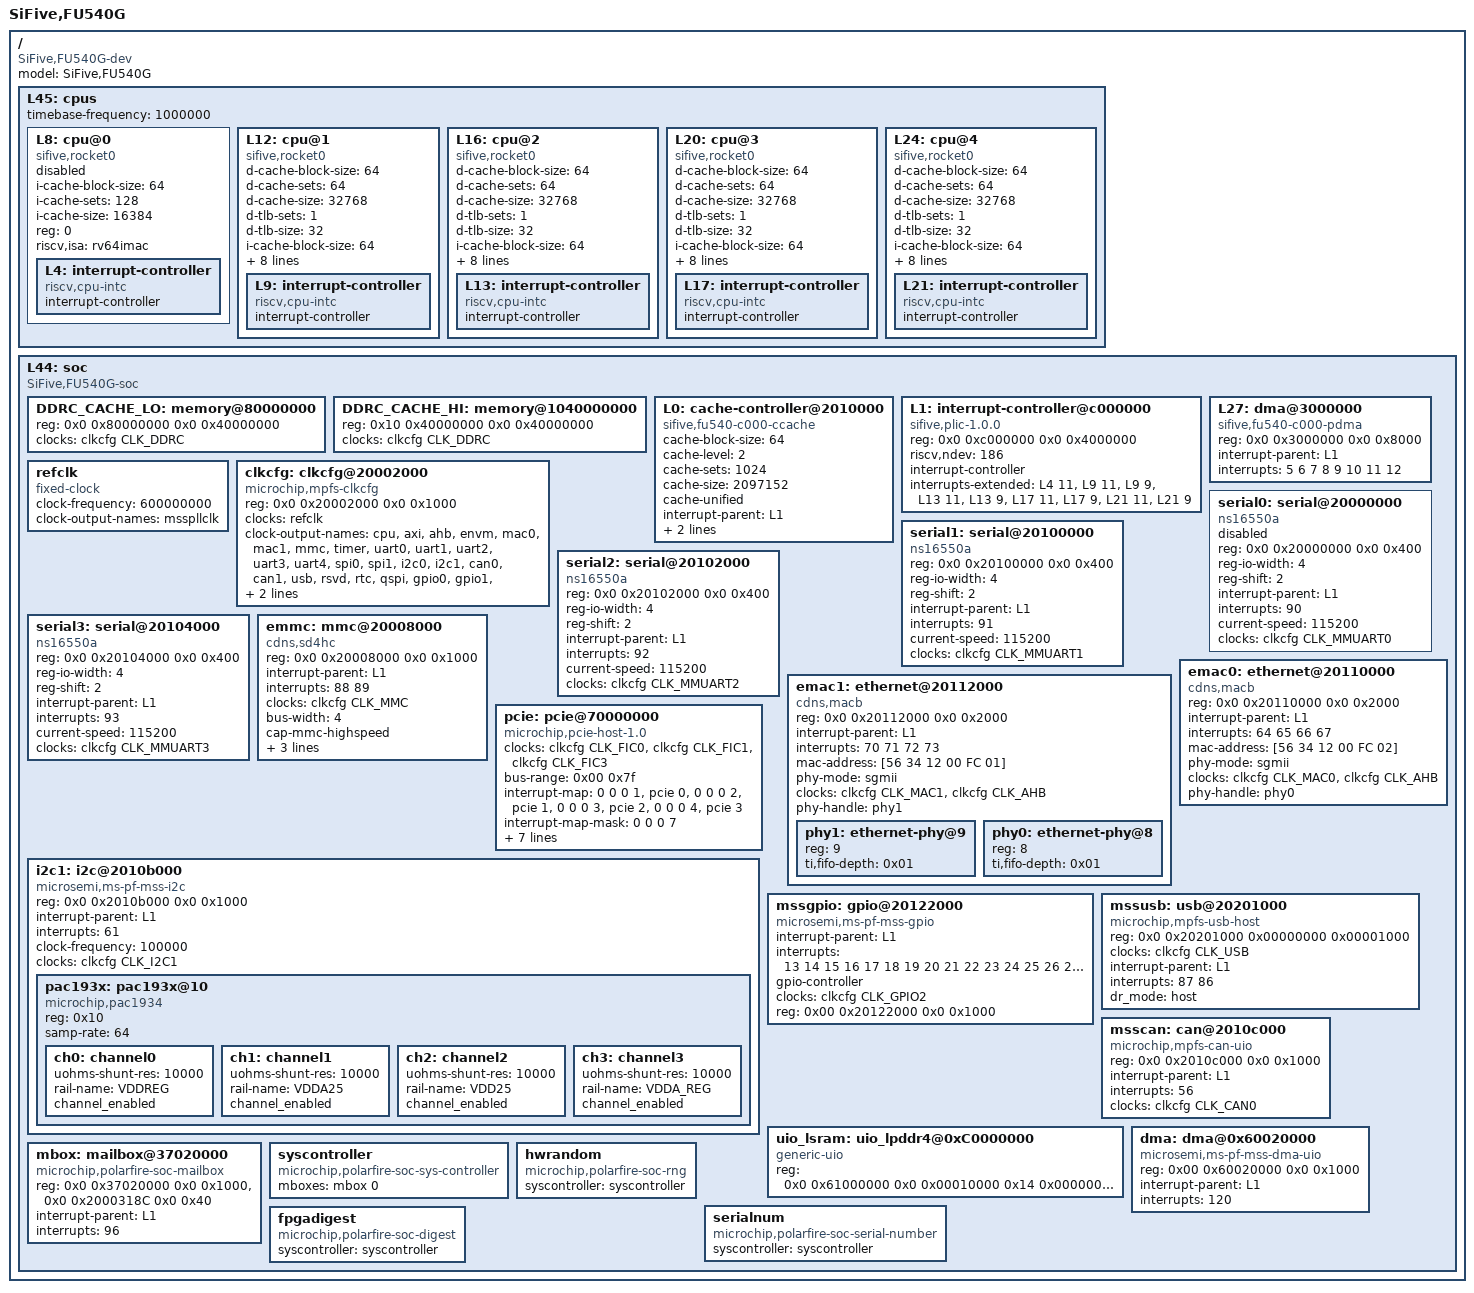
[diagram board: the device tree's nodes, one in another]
// SPDX-License-Identifier: (GPL-2.0 OR MIT)
/* Copyright (c) 2019-2020 Microchip Technology Inc */
/dts-v1/;
#include "dt-bindings/clock/microchip,mpfs-clock.h"
/ {
	#address-cells = <2>;
	#size-cells = <2>;
	compatible = "SiFive,FU540G-dev", "fu540-dev", "sifive-dev";
	model = "SiFive,FU540G";
	L45: cpus {
		#address-cells = <1>;
		#size-cells = <0>;
		timebase-frequency = <1000000>;
		L8: cpu@0 {
			compatible = "sifive,rocket0", "riscv";
			device_type = "cpu";
			i-cache-block-size = <64>;
			i-cache-sets = <128>;
			i-cache-size = <16384>;
			reg = <0>;
			riscv,isa = "rv64imac";
			status = "disabled";
			L4: interrupt-controller {
				#interrupt-cells = <1>;
				compatible = "riscv,cpu-intc";
				interrupt-controller;
			};
		};
		L12: cpu@1 {
			compatible = "sifive,rocket0", "riscv";
			d-cache-block-size = <64>;
			d-cache-sets = <64>;
			d-cache-size = <32768>;
			d-tlb-sets = <1>;
			d-tlb-size = <32>;
			device_type = "cpu";
			i-cache-block-size = <64>;
			i-cache-sets = <64>;
			i-cache-size = <32768>;
			i-tlb-sets = <1>;
			i-tlb-size = <32>;
			mmu-type = "riscv,sv39";
			reg = <1>;
			riscv,isa = "rv64imafdc";
			tlb-split;
			status = "okay";
			L9: interrupt-controller {
				#interrupt-cells = <1>;
				compatible = "riscv,cpu-intc";
				interrupt-controller;
			};
		};
		L16: cpu@2 {
			compatible = "sifive,rocket0", "riscv";
			d-cache-block-size = <64>;
			d-cache-sets = <64>;
			d-cache-size = <32768>;
			d-tlb-sets = <1>;
			d-tlb-size = <32>;
			device_type = "cpu";
			i-cache-block-size = <64>;
			i-cache-sets = <64>;
			i-cache-size = <32768>;
			i-tlb-sets = <1>;
			i-tlb-size = <32>;
			mmu-type = "riscv,sv39";
			reg = <2>;
			riscv,isa = "rv64imafdc";
			tlb-split;
			status = "okay";
			L13: interrupt-controller {
				#interrupt-cells = <1>;
				compatible = "riscv,cpu-intc";
				interrupt-controller;
			};
		};
		L20: cpu@3 {
			compatible = "sifive,rocket0", "riscv";
			d-cache-block-size = <64>;
			d-cache-sets = <64>;
			d-cache-size = <32768>;
			d-tlb-sets = <1>;
			d-tlb-size = <32>;
			device_type = "cpu";
			i-cache-block-size = <64>;
			i-cache-sets = <64>;
			i-cache-size = <32768>;
			i-tlb-sets = <1>;
			i-tlb-size = <32>;
			mmu-type = "riscv,sv39";
			reg = <3>;
			riscv,isa = "rv64imafdc";
			tlb-split;
			status = "okay";
			L17: interrupt-controller {
				#interrupt-cells = <1>;
				compatible = "riscv,cpu-intc";
				interrupt-controller;
			};
		};
		L24: cpu@4 {
			compatible = "sifive,rocket0", "riscv";
			d-cache-block-size = <64>;
			d-cache-sets = <64>;
			d-cache-size = <32768>;
			d-tlb-sets = <1>;
			d-tlb-size = <32>;
			device_type = "cpu";
			i-cache-block-size = <64>;
			i-cache-sets = <64>;
			i-cache-size = <32768>;
			i-tlb-sets = <1>;
			i-tlb-size = <32>;
			mmu-type = "riscv,sv39";
			reg = <4>;
			riscv,isa = "rv64imafdc";
			tlb-split;
			status = "okay";
			L21: interrupt-controller {
				#interrupt-cells = <1>;
				compatible = "riscv,cpu-intc";
				interrupt-controller;
			};
		};
	};
	L44: soc {
		#address-cells = <2>;
		#size-cells = <2>;
		compatible = "SiFive,FU540G-soc", "fu540-soc", "sifive-soc", "simple-bus";
		ranges;
		DDRC_CACHE_LO: memory@80000000 {
			device_type = "memory";
			reg = <0x0 0x80000000 0x0 0x40000000>;
			clocks = <&clkcfg CLK_DDRC>;
			status = "okay";
		};
		DDRC_CACHE_HI: memory@1040000000 {
			device_type = "memory";
			reg = <0x10 0x40000000 0x0 0x40000000>;
			clocks = <&clkcfg CLK_DDRC>;
		};
		L0: cache-controller@2010000 {
			compatible = "sifive,fu540-c000-ccache", "cache";
			cache-block-size = <64>;
			cache-level = <2>;
			cache-sets = <1024>;
			cache-size = <2097152>;
			cache-unified;
			interrupt-parent = <&L1>;
			interrupts = <1 2 3>;
			reg = <0x0 0x2010000 0x0 0x1000>;
		};
		L1: interrupt-controller@c000000 {
			#interrupt-cells = <1>;
			compatible = "sifive,plic-1.0.0";
			reg = <0x0 0xc000000 0x0 0x4000000>;
			riscv,ndev = <186>;
			interrupt-controller;
			interrupts-extended = <&L4 11 &L9 11 &L9 9 &L13 11 &L13 9 &L17 11 &L17 9 &L21 11 &L21 9>;
		};
		L27: dma@3000000 {
			compatible = "sifive,fu540-c000-pdma";
			reg = <0x0 0x3000000 0x0 0x8000>;
			interrupt-parent = <&L1>;
			interrupts = <5 6 7 8 9 10 11 12>;
			#dma-cells = <1>;
		};
		refclk: refclk {
			compatible = "fixed-clock";
			#clock-cells = <0>;
			clock-frequency = <600000000>;
			clock-output-names = "msspllclk";
		};
		clkcfg: clkcfg@20002000 {
			compatible = "microchip,mpfs-clkcfg";
			reg = <0x0 0x20002000 0x0 0x1000>;
			reg-names = "mss_sysreg";
			clocks = <&refclk>;
			#clock-cells = <1>;
			clock-output-names = "cpu", "axi", "ahb", "envm", "mac0", "mac1", "mmc",
					     "timer", "uart0", "uart1", "uart2", "uart3", "uart4",
					     "spi0", "spi1", "i2c0", "i2c1", "can0", "can1", "usb",
					     "rsvd", "rtc", "qspi", "gpio0", "gpio1", "gpio2",
					     "ddrc", "fic0", "fic1", "fic2", "fic3", "athena",
					     "cfm";
		};
		serial0: serial@20000000 {
			compatible = "ns16550a";
			reg = <0x0 0x20000000 0x0 0x400>;
			reg-io-width = <4>;
			reg-shift = <2>;
			interrupt-parent = <&L1>;
			interrupts = <90>;
			current-speed = <115200>;
			clocks = <&clkcfg CLK_MMUART0>;
			status = "disabled"; /* Reserved for the HSS */
		};
		serial1: serial@20100000 {
			compatible = "ns16550a";
			reg = <0x0 0x20100000 0x0 0x400>;
			reg-io-width = <4>;
			reg-shift = <2>;
			interrupt-parent = <&L1>;
			interrupts = <91>;
			current-speed = <115200>;
			clocks = <&clkcfg CLK_MMUART1>;
			status = "okay";
		};
		serial2: serial@20102000 {
			compatible = "ns16550a";
			reg = <0x0 0x20102000 0x0 0x400>;
			reg-io-width = <4>;
			reg-shift = <2>;
			interrupt-parent = <&L1>;
			interrupts = <92>;
			current-speed = <115200>;
			clocks = <&clkcfg CLK_MMUART2>;
			status = "okay";
		};
		serial3: serial@20104000 {
			compatible = "ns16550a";
			reg = <0x0 0x20104000 0x0 0x400>;
			reg-io-width = <4>;
			reg-shift = <2>;
			interrupt-parent = <&L1>;
			interrupts = <93>;
			current-speed = <115200>;
			clocks = <&clkcfg CLK_MMUART3>;
			status = "okay";
		};
		emmc: mmc@20008000 { /* Common node entry for emmc/sd */
		    compatible = "cdns,sd4hc";
		    reg = <0x0 0x20008000 0x0 0x1000>;
		    interrupt-parent = <&L1>;
		    interrupts = <88 89>;
		    pinctrl-names = "default";
		    clocks = <&clkcfg CLK_MMC>;
		    bus-width = <4>;
		    cap-mmc-highspeed;
		    cap-sd-highspeed;
		    disable-wp;
		    max-frequency = <200000000>;
		    status = "okay";
		};
		emac1: ethernet@20112000 {
            compatible = "cdns,macb";
            reg = <0x0 0x20112000 0x0 0x2000>;
            interrupt-parent = <&L1>;
            interrupts = <70 71 72 73>;
            mac-address = [56 34 12 00 FC 01];
            phy-mode = "sgmii";
            clocks = <&clkcfg CLK_MAC1>, <&clkcfg CLK_AHB>;
            clock-names = "pclk", "hclk";
            #address-cells = <1>;
            #size-cells = <0>;
            phy-handle = <&phy1>;
            phy1: ethernet-phy@9 {
                reg = <9>;
                ti,fifo-depth = <0x01>;
            };
            phy0: ethernet-phy@8 {
                reg = <8>;
                ti,fifo-depth = <0x01>;
            };
        };
        emac0: ethernet@20110000 {
            compatible = "cdns,macb";
            reg = <0x0 0x20110000 0x0 0x2000>;
            interrupt-parent = <&L1>;
            interrupts = <64 65 66 67>;
            mac-address = [56 34 12 00 FC 02];
            phy-mode = "sgmii";
            clocks = <&clkcfg CLK_MAC0>, <&clkcfg CLK_AHB>;
            clock-names = "pclk", "hclk";
            phy-handle = <&phy0>;
        };
		pcie: pcie@70000000 {
			#address-cells = <0x3>;
			#interrupt-cells = <0x1>;
			#size-cells = <0x2>;
			compatible = "microchip,pcie-host-1.0";
			device_type = "pci";
			clocks = <&clkcfg CLK_FIC0>, <&clkcfg CLK_FIC1>, <&clkcfg CLK_FIC3>;
			clock-names = "fic0", "fic1", "fic3";
			bus-range = <0x00 0x7f>;
			interrupt-map = <0 0 0 1 &pcie 0>,
					<0 0 0 2 &pcie 1>,
					<0 0 0 3 &pcie 2>,
					<0 0 0 4 &pcie 3>;
			interrupt-map-mask = <0 0 0 7>;
			interrupt-parent = <&L1>;
			interrupts = <119>;
			ranges = <0x03000000 0x0 0x78000000 0x0 0x78000000 0x0 0x04000000>;
			reg = <0x0 0x70000000 0x0 0x08000000 0x0 0x43000000 0x0 0x00010000>;
                        dma-ranges = <0x02000000 0x0 0x00000000 0x0 0x00000000 0x1 0x00000000>;
			reg-names = "cfg", "apb";
			interrupt-controller;
			status = "okay";
		};
		i2c1: i2c@2010b000 {
			#address-cells = <1>;
			#size-cells = <0>;
			compatible = "microsemi,ms-pf-mss-i2c";
			reg = <0x0 0x2010b000 0x0 0x1000>;
			interrupt-parent = <&L1>;
			interrupts = <61>;
			clock-frequency = <100000>;
			clocks = <&clkcfg CLK_I2C1>;
			status = "okay";
			pac193x: pac193x@10 {
				compatible = "microchip,pac1934";
				reg = <0x10>;
				samp-rate = <64>;
				status = "okay";
				ch0: channel0 {
					uohms-shunt-res = <10000>;
					rail-name = "VDDREG";
					channel_enabled;
				};
				ch1: channel1 {
					uohms-shunt-res = <10000>;
					rail-name = "VDDA25";
					channel_enabled;
				};
				ch2: channel2 {
					uohms-shunt-res = <10000>;
					rail-name = "VDD25";
					channel_enabled;
				};
				ch3: channel3 {
					uohms-shunt-res = <10000>;
					rail-name = "VDDA_REG";
					channel_enabled;
				};
			};
		};
		mssgpio: gpio@20122000 {
			compatible = "microsemi,ms-pf-mss-gpio";
			interrupt-parent = <&L1>;
			interrupts = <13 14 15 16 17 18 19 20 21 22 23 24 25 26 27 28 29 30 31 32 33 34 35 36 37 38 39 40 41 42 43 44>;
			gpio-controller;
			clocks = <&clkcfg CLK_GPIO2>;
			reg = <0x00 0x20122000 0x0 0x1000>;
			reg-names = "control";
			#gpio-cells = <2>;
			status = "okay";
		};
                mssusb: usb@20201000 {
                        compatible = "microchip,mpfs-usb-host";
		        reg = <0x0 0x20201000 0x00000000 0x00001000>;
                        reg-names = "mc","control";
                        clocks = <&clkcfg CLK_USB>;
                        interrupt-parent = <&L1>;
                        interrupts = <87 86>;
                        interrupt-names = "mc","dma";
                        dr_mode = "host";
                        status = "okay";
               };
               msscan: can@2010c000 {
                       #address-cells = <1>;
                       #size-cells = <0>;
                       compatible = "microchip,mpfs-can-uio";
                       reg = <0x0 0x2010c000 0x0 0x1000>;
                       interrupt-parent = <&L1>;
                       interrupts = <56>;
                       clocks = <&clkcfg CLK_CAN0>;
                       status = "okay";
              };
              uio_lsram: uio_lpddr4@0xC0000000 {
                       compatible = "generic-uio";
                       reg = < 0x0 0x61000000 0x0 0x00010000
                             0x14 0x00000000 0x0 0x00010000 >;
                       status = "okay";
              };
              dma: dma@0x60020000 {
                       #address-cells = <1>;
                       #size-cells = <0>;
                       compatible = "microsemi,ms-pf-mss-dma-uio";
                       reg = <0x00 0x60020000 0x0 0x1000>;
                       interrupt-parent = <&L1>;
                       interrupts = <120>;
                       status = "okay";
              };
              mbox: mailbox@37020000 {
                        compatible = "microchip,polarfire-soc-mailbox";
                        reg = <0x0 0x37020000 0x0 0x1000>, <0x0 0x2000318C 0x0 0x40>;
                        interrupt-parent = <&L1>;
                        interrupts = <96>;
                        #mbox-cells = <1>;
               };
               syscontroller: syscontroller {
                        compatible = "microchip,polarfire-soc-sys-controller";
                        #address-cells = <1>;
                        #size-cells = <1>;
                        mboxes = <&mbox 0>;
               };
               hwrandom: hwrandom {
                        compatible = "microchip,polarfire-soc-rng";
                        #address-cells = <1>;
                        #size-cells = <1>;
                        syscontroller = <&syscontroller>;
                };
                serialnum: serialnum {
                        compatible = "microchip,polarfire-soc-serial-number";
                        #address-cells = <1>;
                        #size-cells = <1>;
                        syscontroller = <&syscontroller>;
                };
                fpgadigest: fpgadigest {
                        compatible = "microchip,polarfire-soc-digest";
                        #address-cells = <1>;
                        #size-cells = <1>;
                        syscontroller = <&syscontroller>;
                };
	};
};
